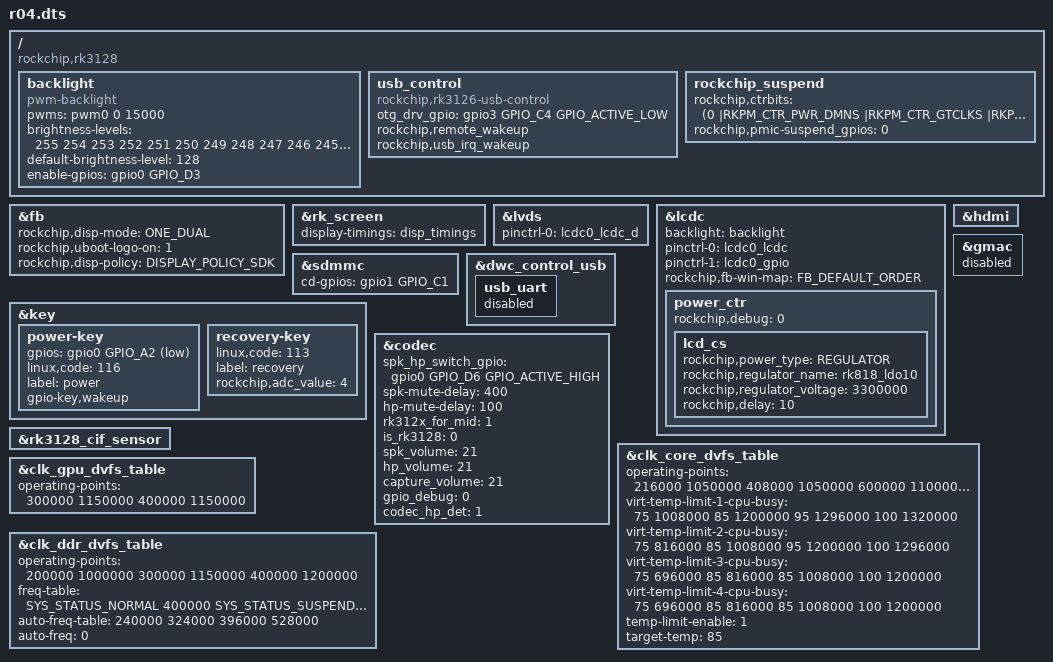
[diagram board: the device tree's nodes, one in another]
/dts-v1/;

#include "rk3128.dtsi"
#include "rk3128-cif-sensor.dtsi"
//#include "rk312x-r04.dtsi"//nix 8723bs
#include "rk312x-nix_8723bu.dtsi"
//#include "lcd-ttl7.dtsi"
#include "lcd-nix8.0.dtsi"
//#include "lcd-nix9.7.dtsi"
//#include "lcd-1024x768-mipi.dtsi"
//#include "lcd-b080xan03.0-mipi.dtsi"
/ {
	 compatible = "rockchip,rk3128";
        backlight: backlight {
                compatible = "pwm-backlight";
                pwms = <&pwm0 0 15000>;
              /*  brightness-levels = <0 1 2 3 4 5 6 7 8 9 10 11 12 13 14 15 16 17 18 19 20 21 22 23 24 25 26 27 28 29 30 31 32 33 34 35 36 37 38 39 40 41 42 43 44 45 46 47 48 49 50 51 52 53 54 55 56 57 58 59 60 61 62 63 64 65 66 67 68 69 70 71 72 73 74 75 76 77 78 79 80 81 82 83 84 85 86 87 88 89 90 91 92 93 94 95 96 97 98 99 100 101 102 103 104 105 106 107 108 109 110 111 112 113 114 115 116 117 118 119 120 121 122 123 124 125 126 127 128 129 130 131 132 133 134 135 136 137 138 139 140 141 142 143 144 145 146 147 148 149 150 151 152 153 154 155 156 157 158 159 160 161 162 163 164 165 166 167 168 169 170 171 172 173 174 175 176 177 178 179 180 181 182 183 184 185 186 187 188 189 190 191 192 193 194 195 196 197 198 199 200 201 202 203 204 205 206 207 208 209 210 211 212 213 214 215 216 217 218 219 220 221 222 223 224 225 226 227 228 229 230 231 232 233 234 235 236 237 238 239 240 241 242 243 244 245 246 247 248 249 250 251 252 253 254 255>;*/
        brightness-levels = <255 254 253 252 251 250 249 248 247 246 245 244 243 242 241 240 239 238 237 236 235 234 233 232 231 230 229 228 227 226 225 224 223 222 221 220 219 218 217 216 215 214 213 212 211 210 209 208 207 206 205 204 203 202 201 200 199 198 197 196 195 194 193 192 191 190 189 188 187 186 185 184 183 182 181 180 179 178 177 176 175 174 173 172 171 170 169 168 167 166 165 164 163 162 161 160>;        
	default-brightness-level = <128>;
                enable-gpios = <&gpio0 GPIO_D3 GPIO_ACTIVE_HIGH>;
        };

	usb_control {
		compatible = "rockchip,rk3126-usb-control";

		otg_drv_gpio = <&gpio3 GPIO_C4 GPIO_ACTIVE_LOW>;

		rockchip,remote_wakeup;
		rockchip,usb_irq_wakeup;
	};
	 rockchip_suspend {
                rockchip,ctrbits = <
                        (0
                        |RKPM_CTR_PWR_DMNS
                        |RKPM_CTR_GTCLKS
                        |RKPM_CTR_PLLS
                        //|RKPM_CTR_ARMOFF_LPMD
                        |RKPM_CTR_DDR
                        |RKPM_CTR_IDLESRAM_MD
                        |RKPM_CTR_DDR
                        //|RKPM_CTR_BUS_IDLE
			//|RKPM_CTR_VOLTS
			//|RKPM_CTR_VOL_PWM1
			//|RKPM_CTR_VOL_PWM2
                        )
                >;
               rockchip,pmic-suspend_gpios = <
                       0
                        >;
        };
};

&fb {
	rockchip,disp-mode = <ONE_DUAL>;
	rockchip,uboot-logo-on = <1>;
	rockchip,disp-policy = <DISPLAY_POLICY_SDK>;
};

&rk_screen {
	display-timings = <&disp_timings>;
};

&lvds {
	status = "okay";

	pinctrl-names = "lcdc";
	pinctrl-0 = <&lcdc0_lcdc_d>;
};

&lcdc {
	status = "okay";

	backlight = <&backlight>;
	pinctrl-names = "default", "gpio";
	pinctrl-0 = <&lcdc0_lcdc>;
	pinctrl-1 = <&lcdc0_gpio>;

	rockchip,fb-win-map = <FB_DEFAULT_ORDER>;
	power_ctr: power_ctr {
		rockchip,debug = <0>;
		lcd_cs: lcd_cs {
			rockchip,power_type = <REGULATOR>;
			rockchip,regulator_name = "rk818_ldo10";
			rockchip,regulator_voltage = <3300000>;
			//gpios = <&gpio0 GPIO_D0 GPIO_ACTIVE_HIGH>;
			rockchip,delay = <10>;
		};
	};
};

&hdmi {
        status = "okay";
};

&sdmmc {
	cd-gpios = <&gpio1 GPIO_C1 GPIO_ACTIVE_HIGH>;/*CD GPIO*/
	status = "okay";
};
&key {
		power-key {
			gpios = <&gpio0 GPIO_A2 GPIO_ACTIVE_LOW>;
			linux,code = <116>;
			label = "power";
			gpio-key,wakeup;
		};
		recovery-key {
                        linux,code = <113>;
                        label = "recovery";
                        rockchip,adc_value = <4>;
        };
};

&dwc_control_usb {
	usb_uart {
		status = "disabled";
	};
};
&codec {
	spk_hp_switch_gpio = <&gpio0 GPIO_D6 GPIO_ACTIVE_HIGH>;
        spk-mute-delay = <400>;
        hp-mute-delay = <100>;
        rk312x_for_mid = <1>;
        is_rk3128 = <0>;
        spk_volume = <21>;
        hp_volume = <21>;
        capture_volume = <21>;
        gpio_debug = <0>;
        codec_hp_det = <1>;
		
};

&rk3128_cif_sensor{
	status = "okay";
};
 
&gmac {
	status = "disabled";
};
 
&clk_core_dvfs_table {
	operating-points = <
		/* KHz    uV */
		216000  1050000
		408000  1050000
		600000  1100000
		696000  1100000
		816000  1150000
		1008000 1250000
		1200000 1350000
//		1296000 1400000
//		1320000 1425000
		>;
	virt-temp-limit-1-cpu-busy = <
	/* target-temp	limit-freq */
		75	1008000
		85	1200000
		95	1296000
		100	1320000
		>;
	virt-temp-limit-2-cpu-busy = <
	/* target-temp	limit-freq */
		75	816000
		85	1008000
		95	1200000
		100	1296000
		>;
	virt-temp-limit-3-cpu-busy = <
	/* target-temp	limit-freq */
		75	696000
		85	816000
		85	1008000
		100	1200000
		>;
	virt-temp-limit-4-cpu-busy = <
	/* target-temp	limit-freq */
		75	696000
		85	816000
		85	1008000
		100	1200000
		>;
	temp-limit-enable = <1>;
	target-temp = <85>;
	status="okay";
};

&clk_gpu_dvfs_table {
	operating-points = <
		/* KHz    uV */
	//	200000 1200000
		300000 1150000
		400000 1150000
	//	480000 1200000
		>;
	status="okay";
};

&clk_ddr_dvfs_table {
	operating-points = <
		/* KHz    uV */
		200000 1000000
		300000 1150000
		400000 1200000
//		533000 1250000
		>;

	freq-table = <
		/*status		freq(KHz)*/
		SYS_STATUS_NORMAL	400000
		SYS_STATUS_SUSPEND	300000
/*
		SYS_STATUS_VIDEO_1080P  436000
		SYS_STATUS_VIDEO_4K     400000
		SYS_STATUS_PERFORMANCE  528000
		SYS_STATUS_DUALVIEW	400000
		SYS_STATUS_BOOST	324000
		SYS_STATUS_ISP		533000
*/
		>;
	auto-freq-table = <
		240000
		324000
		396000
		528000
		>;
	auto-freq=<0>;
	status="okay";
};
